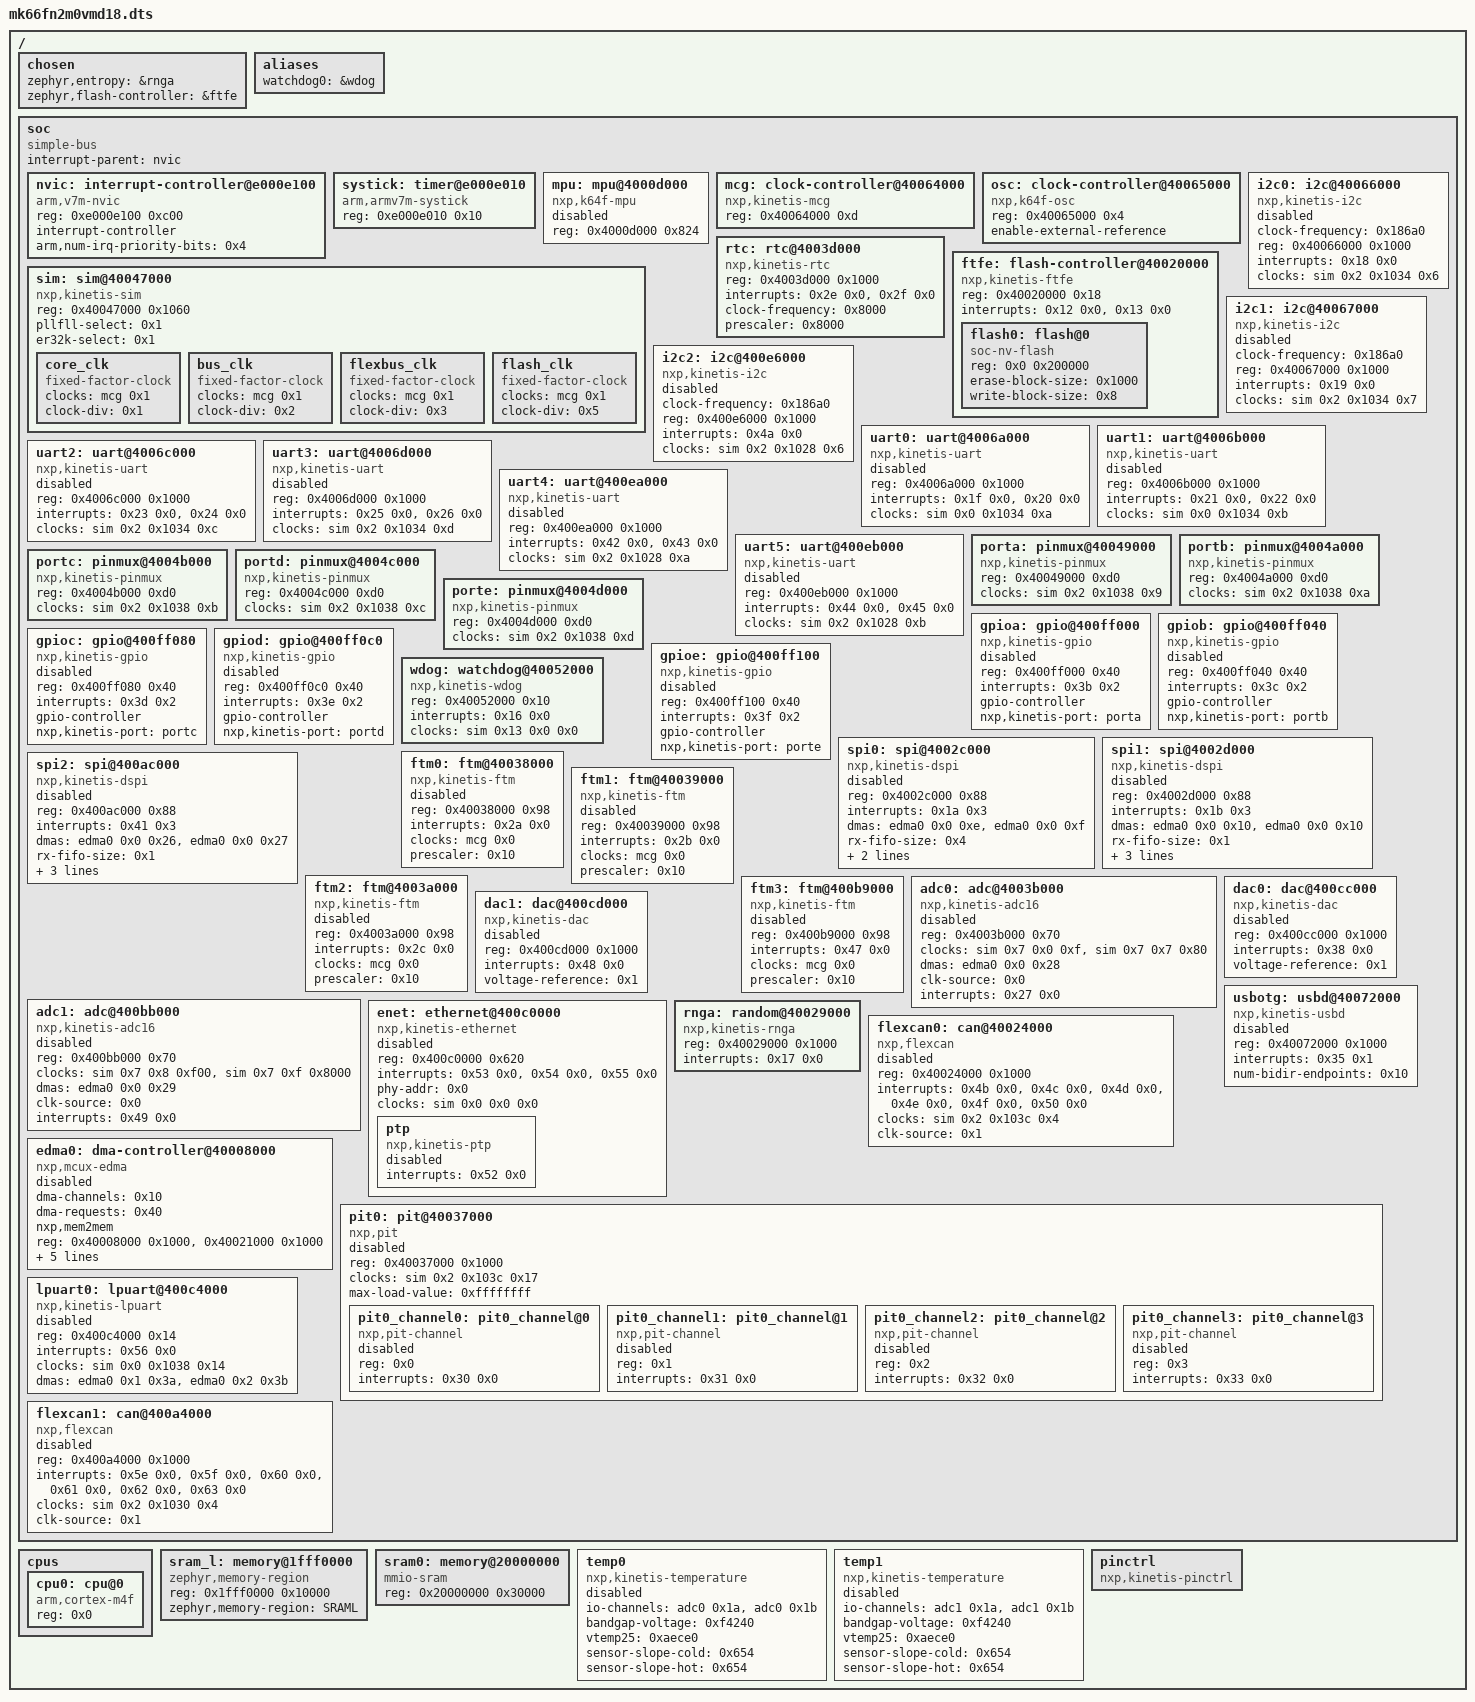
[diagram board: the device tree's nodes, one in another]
/dts-v1/;

/ {
	#address-cells = < 0x1 >;
	#size-cells = < 0x1 >;
	chosen {
		zephyr,entropy = &rnga;
		zephyr,flash-controller = &ftfe;
	};
	aliases {
		watchdog0 = &wdog;
	};
	soc {
		#address-cells = < 0x1 >;
		#size-cells = < 0x1 >;
		compatible = "simple-bus";
		interrupt-parent = < &nvic >;
		ranges;
		nvic: interrupt-controller@e000e100 {
			#address-cells = < 0x1 >;
			compatible = "arm,v7m-nvic";
			reg = < 0xe000e100 0xc00 >;
			interrupt-controller;
			#interrupt-cells = < 0x2 >;
			arm,num-irq-priority-bits = < 0x4 >;
			phandle = < 0x1 >;
		};
		systick: timer@e000e010 {
			compatible = "arm,armv7m-systick";
			reg = < 0xe000e010 0x10 >;
		};
		mpu: mpu@4000d000 {
			compatible = "nxp,k64f-mpu";
			reg = < 0x4000d000 0x824 >;
			status = "disabled";
		};
		mcg: clock-controller@40064000 {
			compatible = "nxp,kinetis-mcg";
			reg = < 0x40064000 0xd >;
			#clock-cells = < 0x1 >;
			phandle = < 0x2 >;
		};
		osc: clock-controller@40065000 {
			compatible = "nxp,k64f-osc";
			reg = < 0x40065000 0x4 >;
			enable-external-reference;
		};
		rtc: rtc@4003d000 {
			compatible = "nxp,kinetis-rtc";
			reg = < 0x4003d000 0x1000 >;
			interrupts = < 0x2e 0x0 >, < 0x2f 0x0 >;
			interrupt-names = "alarm", "seconds";
			clock-frequency = < 0x8000 >;
			prescaler = < 0x8000 >;
		};
		sim: sim@40047000 {
			compatible = "nxp,kinetis-sim";
			reg = < 0x40047000 0x1060 >;
			#clock-cells = < 0x3 >;
			pllfll-select = < 0x1 >;
			er32k-select = < 0x1 >;
			phandle = < 0x3 >;
			core_clk {
				compatible = "fixed-factor-clock";
				clocks = < &mcg 0x1 >;
				clock-div = < 0x1 >;
				#clock-cells = < 0x0 >;
			};
			bus_clk {
				compatible = "fixed-factor-clock";
				clocks = < &mcg 0x1 >;
				clock-div = < 0x2 >;
				#clock-cells = < 0x0 >;
			};
			flexbus_clk {
				compatible = "fixed-factor-clock";
				clocks = < &mcg 0x1 >;
				clock-div = < 0x3 >;
				#clock-cells = < 0x0 >;
			};
			flash_clk {
				compatible = "fixed-factor-clock";
				clocks = < &mcg 0x1 >;
				clock-div = < 0x5 >;
				#clock-cells = < 0x0 >;
			};
		};
		ftfe: flash-controller@40020000 {
			compatible = "nxp,kinetis-ftfe";
			reg = < 0x40020000 0x18 >;
			interrupts = < 0x12 0x0 >, < 0x13 0x0 >;
			interrupt-names = "command-complete", "read-collision";
			status = "okay";
			#address-cells = < 0x1 >;
			#size-cells = < 0x1 >;
			flash0: flash@0 {
				compatible = "soc-nv-flash";
				reg = < 0x0 0x200000 >;
				erase-block-size = < 0x1000 >;
				write-block-size = < 0x8 >;
			};
		};
		i2c0: i2c@40066000 {
			compatible = "nxp,kinetis-i2c";
			clock-frequency = < 0x186a0 >;
			#address-cells = < 0x1 >;
			#size-cells = < 0x0 >;
			reg = < 0x40066000 0x1000 >;
			interrupts = < 0x18 0x0 >;
			clocks = < &sim 0x2 0x1034 0x6 >;
			status = "disabled";
		};
		i2c1: i2c@40067000 {
			compatible = "nxp,kinetis-i2c";
			clock-frequency = < 0x186a0 >;
			#address-cells = < 0x1 >;
			#size-cells = < 0x0 >;
			reg = < 0x40067000 0x1000 >;
			interrupts = < 0x19 0x0 >;
			clocks = < &sim 0x2 0x1034 0x7 >;
			status = "disabled";
		};
		i2c2: i2c@400e6000 {
			compatible = "nxp,kinetis-i2c";
			clock-frequency = < 0x186a0 >;
			#address-cells = < 0x1 >;
			#size-cells = < 0x0 >;
			reg = < 0x400e6000 0x1000 >;
			interrupts = < 0x4a 0x0 >;
			clocks = < &sim 0x2 0x1028 0x6 >;
			status = "disabled";
		};
		uart0: uart@4006a000 {
			compatible = "nxp,kinetis-uart";
			reg = < 0x4006a000 0x1000 >;
			interrupts = < 0x1f 0x0 >, < 0x20 0x0 >;
			interrupt-names = "status", "error";
			clocks = < &sim 0x0 0x1034 0xa >;
			status = "disabled";
		};
		uart1: uart@4006b000 {
			compatible = "nxp,kinetis-uart";
			reg = < 0x4006b000 0x1000 >;
			interrupts = < 0x21 0x0 >, < 0x22 0x0 >;
			interrupt-names = "status", "error";
			clocks = < &sim 0x0 0x1034 0xb >;
			status = "disabled";
		};
		uart2: uart@4006c000 {
			compatible = "nxp,kinetis-uart";
			reg = < 0x4006c000 0x1000 >;
			interrupts = < 0x23 0x0 >, < 0x24 0x0 >;
			interrupt-names = "status", "error";
			clocks = < &sim 0x2 0x1034 0xc >;
			status = "disabled";
		};
		uart3: uart@4006d000 {
			compatible = "nxp,kinetis-uart";
			reg = < 0x4006d000 0x1000 >;
			interrupts = < 0x25 0x0 >, < 0x26 0x0 >;
			interrupt-names = "status", "error";
			clocks = < &sim 0x2 0x1034 0xd >;
			status = "disabled";
		};
		uart4: uart@400ea000 {
			compatible = "nxp,kinetis-uart";
			reg = < 0x400ea000 0x1000 >;
			interrupts = < 0x42 0x0 >, < 0x43 0x0 >;
			interrupt-names = "status", "error";
			clocks = < &sim 0x2 0x1028 0xa >;
			status = "disabled";
		};
		uart5: uart@400eb000 {
			compatible = "nxp,kinetis-uart";
			reg = < 0x400eb000 0x1000 >;
			interrupts = < 0x44 0x0 >, < 0x45 0x0 >;
			interrupt-names = "status", "error";
			clocks = < &sim 0x2 0x1028 0xb >;
			status = "disabled";
		};
		porta: pinmux@40049000 {
			compatible = "nxp,kinetis-pinmux";
			reg = < 0x40049000 0xd0 >;
			clocks = < &sim 0x2 0x1038 0x9 >;
			phandle = < 0x4 >;
		};
		portb: pinmux@4004a000 {
			compatible = "nxp,kinetis-pinmux";
			reg = < 0x4004a000 0xd0 >;
			clocks = < &sim 0x2 0x1038 0xa >;
			phandle = < 0x5 >;
		};
		portc: pinmux@4004b000 {
			compatible = "nxp,kinetis-pinmux";
			reg = < 0x4004b000 0xd0 >;
			clocks = < &sim 0x2 0x1038 0xb >;
			phandle = < 0x6 >;
		};
		portd: pinmux@4004c000 {
			compatible = "nxp,kinetis-pinmux";
			reg = < 0x4004c000 0xd0 >;
			clocks = < &sim 0x2 0x1038 0xc >;
			phandle = < 0x7 >;
		};
		porte: pinmux@4004d000 {
			compatible = "nxp,kinetis-pinmux";
			reg = < 0x4004d000 0xd0 >;
			clocks = < &sim 0x2 0x1038 0xd >;
			phandle = < 0x8 >;
		};
		gpioa: gpio@400ff000 {
			compatible = "nxp,kinetis-gpio";
			status = "disabled";
			reg = < 0x400ff000 0x40 >;
			interrupts = < 0x3b 0x2 >;
			gpio-controller;
			#gpio-cells = < 0x2 >;
			nxp,kinetis-port = < &porta >;
		};
		gpiob: gpio@400ff040 {
			compatible = "nxp,kinetis-gpio";
			status = "disabled";
			reg = < 0x400ff040 0x40 >;
			interrupts = < 0x3c 0x2 >;
			gpio-controller;
			#gpio-cells = < 0x2 >;
			nxp,kinetis-port = < &portb >;
		};
		gpioc: gpio@400ff080 {
			compatible = "nxp,kinetis-gpio";
			status = "disabled";
			reg = < 0x400ff080 0x40 >;
			interrupts = < 0x3d 0x2 >;
			gpio-controller;
			#gpio-cells = < 0x2 >;
			nxp,kinetis-port = < &portc >;
		};
		gpiod: gpio@400ff0c0 {
			compatible = "nxp,kinetis-gpio";
			status = "disabled";
			reg = < 0x400ff0c0 0x40 >;
			interrupts = < 0x3e 0x2 >;
			gpio-controller;
			#gpio-cells = < 0x2 >;
			nxp,kinetis-port = < &portd >;
		};
		gpioe: gpio@400ff100 {
			compatible = "nxp,kinetis-gpio";
			status = "disabled";
			reg = < 0x400ff100 0x40 >;
			interrupts = < 0x3f 0x2 >;
			gpio-controller;
			#gpio-cells = < 0x2 >;
			nxp,kinetis-port = < &porte >;
		};
		spi0: spi@4002c000 {
			compatible = "nxp,kinetis-dspi";
			reg = < 0x4002c000 0x88 >;
			interrupts = < 0x1a 0x3 >;
			dmas = < &edma0 0x0 0xe >, < &edma0 0x0 0xf >;
			dma-names = "rx", "tx";
			rx-fifo-size = < 0x4 >;
			tx-fifo-size = < 0x4 >;
			clocks = < &sim 0x2 0x103c 0xc >;
			#address-cells = < 0x1 >;
			#size-cells = < 0x0 >;
			status = "disabled";
		};
		spi1: spi@4002d000 {
			compatible = "nxp,kinetis-dspi";
			reg = < 0x4002d000 0x88 >;
			interrupts = < 0x1b 0x3 >;
			dmas = < &edma0 0x0 0x10 >, < &edma0 0x0 0x10 >;
			dma-names = "rx", "tx";
			rx-fifo-size = < 0x1 >;
			tx-fifo-size = < 0x1 >;
			nxp,rx-tx-chn-share;
			clocks = < &sim 0x2 0x103c 0xd >;
			#address-cells = < 0x1 >;
			#size-cells = < 0x0 >;
			status = "disabled";
		};
		spi2: spi@400ac000 {
			compatible = "nxp,kinetis-dspi";
			reg = < 0x400ac000 0x88 >;
			interrupts = < 0x41 0x3 >;
			dmas = < &edma0 0x0 0x26 >, < &edma0 0x0 0x27 >;
			dma-names = "rx", "tx";
			rx-fifo-size = < 0x1 >;
			tx-fifo-size = < 0x1 >;
			nxp,rx-tx-chn-share;
			clocks = < &sim 0x2 0x1030 0xc >;
			#address-cells = < 0x1 >;
			#size-cells = < 0x0 >;
			status = "disabled";
		};
		wdog: watchdog@40052000 {
			compatible = "nxp,kinetis-wdog";
			reg = < 0x40052000 0x10 >;
			interrupts = < 0x16 0x0 >;
			clocks = < &sim 0x13 0x0 0x0 >;
		};
		ftm0: ftm@40038000 {
			compatible = "nxp,kinetis-ftm";
			reg = < 0x40038000 0x98 >;
			interrupts = < 0x2a 0x0 >;
			clocks = < &mcg 0x0 >;
			prescaler = < 0x10 >;
			status = "disabled";
		};
		ftm1: ftm@40039000 {
			compatible = "nxp,kinetis-ftm";
			reg = < 0x40039000 0x98 >;
			interrupts = < 0x2b 0x0 >;
			clocks = < &mcg 0x0 >;
			prescaler = < 0x10 >;
			status = "disabled";
		};
		ftm2: ftm@4003a000 {
			compatible = "nxp,kinetis-ftm";
			reg = < 0x4003a000 0x98 >;
			interrupts = < 0x2c 0x0 >;
			clocks = < &mcg 0x0 >;
			prescaler = < 0x10 >;
			status = "disabled";
		};
		ftm3: ftm@400b9000 {
			compatible = "nxp,kinetis-ftm";
			reg = < 0x400b9000 0x98 >;
			interrupts = < 0x47 0x0 >;
			clocks = < &mcg 0x0 >;
			prescaler = < 0x10 >;
			status = "disabled";
		};
		adc0: adc@4003b000 {
			compatible = "nxp,kinetis-adc16";
			reg = < 0x4003b000 0x70 >;
			clocks = < &sim 0x7 0x0 0xf >, < &sim 0x7 0x7 0x80 >;
			dmas = < &edma0 0x0 0x28 >;
			dma-names = "adc0";
			clk-source = < 0x0 >;
			interrupts = < 0x27 0x0 >;
			status = "disabled";
			#io-channel-cells = < 0x1 >;
			phandle = < 0xa >;
		};
		adc1: adc@400bb000 {
			compatible = "nxp,kinetis-adc16";
			reg = < 0x400bb000 0x70 >;
			clocks = < &sim 0x7 0x8 0xf00 >, < &sim 0x7 0xf 0x8000 >;
			dmas = < &edma0 0x0 0x29 >;
			dma-names = "adc1";
			clk-source = < 0x0 >;
			interrupts = < 0x49 0x0 >;
			status = "disabled";
			#io-channel-cells = < 0x1 >;
			phandle = < 0xb >;
		};
		dac0: dac@400cc000 {
			compatible = "nxp,kinetis-dac";
			reg = < 0x400cc000 0x1000 >;
			interrupts = < 0x38 0x0 >;
			voltage-reference = < 0x1 >;
			status = "disabled";
			#io-channel-cells = < 0x1 >;
		};
		dac1: dac@400cd000 {
			compatible = "nxp,kinetis-dac";
			reg = < 0x400cd000 0x1000 >;
			interrupts = < 0x48 0x0 >;
			voltage-reference = < 0x1 >;
			status = "disabled";
			#io-channel-cells = < 0x1 >;
		};
		usbotg: usbd@40072000 {
			compatible = "nxp,kinetis-usbd";
			reg = < 0x40072000 0x1000 >;
			interrupts = < 0x35 0x1 >;
			interrupt-names = "usb_otg";
			num-bidir-endpoints = < 0x10 >;
			status = "disabled";
		};
		enet: ethernet@400c0000 {
			compatible = "nxp,kinetis-ethernet";
			reg = < 0x400c0000 0x620 >;
			interrupts = < 0x53 0x0 >, < 0x54 0x0 >, < 0x55 0x0 >;
			interrupt-names = "TX", "RX", "ERR";
			status = "disabled";
			phy-addr = < 0x0 >;
			clocks = < &sim 0x0 0x0 0x0 >;
			ptp: ptp {
				compatible = "nxp,kinetis-ptp";
				status = "disabled";
				interrupts = < 0x52 0x0 >;
				interrupt-names = "IEEE1588_TMR";
			};
		};
		rnga: random@40029000 {
			compatible = "nxp,kinetis-rnga";
			reg = < 0x40029000 0x1000 >;
			status = "okay";
			interrupts = < 0x17 0x0 >;
		};
		flexcan0: can@40024000 {
			compatible = "nxp,flexcan";
			reg = < 0x40024000 0x1000 >;
			interrupts = < 0x4b 0x0 >, < 0x4c 0x0 >, < 0x4d 0x0 >, < 0x4e 0x0 >, < 0x4f 0x0 >, < 0x50 0x0 >;
			interrupt-names = "mb-0-15", "bus-off", "error", "tx-warning", "rx-warning", "wake-up";
			clocks = < &sim 0x2 0x103c 0x4 >;
			clk-source = < 0x1 >;
			status = "disabled";
		};
		edma0: dma-controller@40008000 {
			#dma-cells = < 0x2 >;
			compatible = "nxp,mcux-edma";
			dma-channels = < 0x10 >;
			dma-requests = < 0x40 >;
			nxp,mem2mem;
			reg = < 0x40008000 0x1000 >, < 0x40021000 0x1000 >;
			interrupts = < 0x0 0x0 >, < 0x1 0x0 >, < 0x2 0x0 >, < 0x3 0x0 >, < 0x4 0x0 >, < 0x5 0x0 >, < 0x6 0x0 >, < 0x7 0x0 >, < 0x8 0x0 >, < 0x9 0x0 >, < 0xa 0x0 >, < 0xb 0x0 >, < 0xc 0x0 >, < 0xd 0x0 >, < 0xe 0x0 >, < 0xf 0x0 >, < 0x10 0x0 >;
			clocks = < &sim 0x0 0x1040 0x2 >, < &sim 0x2 0x103c 0x2 >;
			status = "disabled";
			phandle = < 0x9 >;
		};
		pit0: pit@40037000 {
			compatible = "nxp,pit";
			reg = < 0x40037000 0x1000 >;
			clocks = < &sim 0x2 0x103c 0x17 >;
			status = "disabled";
			max-load-value = < 0xffffffff >;
			#address-cells = < 0x1 >;
			#size-cells = < 0x0 >;
			pit0_channel0: pit0_channel@0 {
				compatible = "nxp,pit-channel";
				reg = < 0x0 >;
				interrupts = < 0x30 0x0 >;
				status = "disabled";
			};
			pit0_channel1: pit0_channel@1 {
				compatible = "nxp,pit-channel";
				reg = < 0x1 >;
				interrupts = < 0x31 0x0 >;
				status = "disabled";
			};
			pit0_channel2: pit0_channel@2 {
				compatible = "nxp,pit-channel";
				reg = < 0x2 >;
				interrupts = < 0x32 0x0 >;
				status = "disabled";
			};
			pit0_channel3: pit0_channel@3 {
				compatible = "nxp,pit-channel";
				reg = < 0x3 >;
				interrupts = < 0x33 0x0 >;
				status = "disabled";
			};
		};
		lpuart0: lpuart@400c4000 {
			compatible = "nxp,kinetis-lpuart";
			reg = < 0x400c4000 0x14 >;
			interrupts = < 0x56 0x0 >;
			clocks = < &sim 0x0 0x1038 0x14 >;
			dmas = < &edma0 0x1 0x3a >, < &edma0 0x2 0x3b >;
			dma-names = "rx", "tx";
			status = "disabled";
		};
		flexcan1: can@400a4000 {
			compatible = "nxp,flexcan";
			reg = < 0x400a4000 0x1000 >;
			interrupts = < 0x5e 0x0 >, < 0x5f 0x0 >, < 0x60 0x0 >, < 0x61 0x0 >, < 0x62 0x0 >, < 0x63 0x0 >;
			interrupt-names = "mb-0-15", "bus-off", "error", "tx-warning", "rx-warning", "wake-up";
			clocks = < &sim 0x2 0x1030 0x4 >;
			clk-source = < 0x1 >;
			status = "disabled";
		};
	};
	cpus {
		#address-cells = < 0x1 >;
		#size-cells = < 0x0 >;
		cpu0: cpu@0 {
			device_type = "cpu";
			compatible = "arm,cortex-m4f";
			reg = < 0x0 >;
		};
	};
	sram_l: memory@1fff0000 {
		compatible = "zephyr,memory-region", "mmio-sram";
		reg = < 0x1fff0000 0x10000 >;
		zephyr,memory-region = "SRAML";
	};
	sram0: memory@20000000 {
		compatible = "mmio-sram";
		reg = < 0x20000000 0x30000 >;
	};
	temp0: temp0 {
		compatible = "nxp,kinetis-temperature";
		io-channels = < &adc0 0x1a >, < &adc0 0x1b >;
		io-channel-names = "SENSOR", "BANDGAP";
		bandgap-voltage = < 0xf4240 >;
		vtemp25 = < 0xaece0 >;
		sensor-slope-cold = < 0x654 >;
		sensor-slope-hot = < 0x654 >;
		status = "disabled";
	};
	temp1: temp1 {
		compatible = "nxp,kinetis-temperature";
		io-channels = < &adc1 0x1a >, < &adc1 0x1b >;
		io-channel-names = "SENSOR", "BANDGAP";
		bandgap-voltage = < 0xf4240 >;
		vtemp25 = < 0xaece0 >;
		sensor-slope-cold = < 0x654 >;
		sensor-slope-hot = < 0x654 >;
		status = "disabled";
	};
	pinctrl: pinctrl {
		compatible = "nxp,kinetis-pinctrl";
		status = "okay";
	};
};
